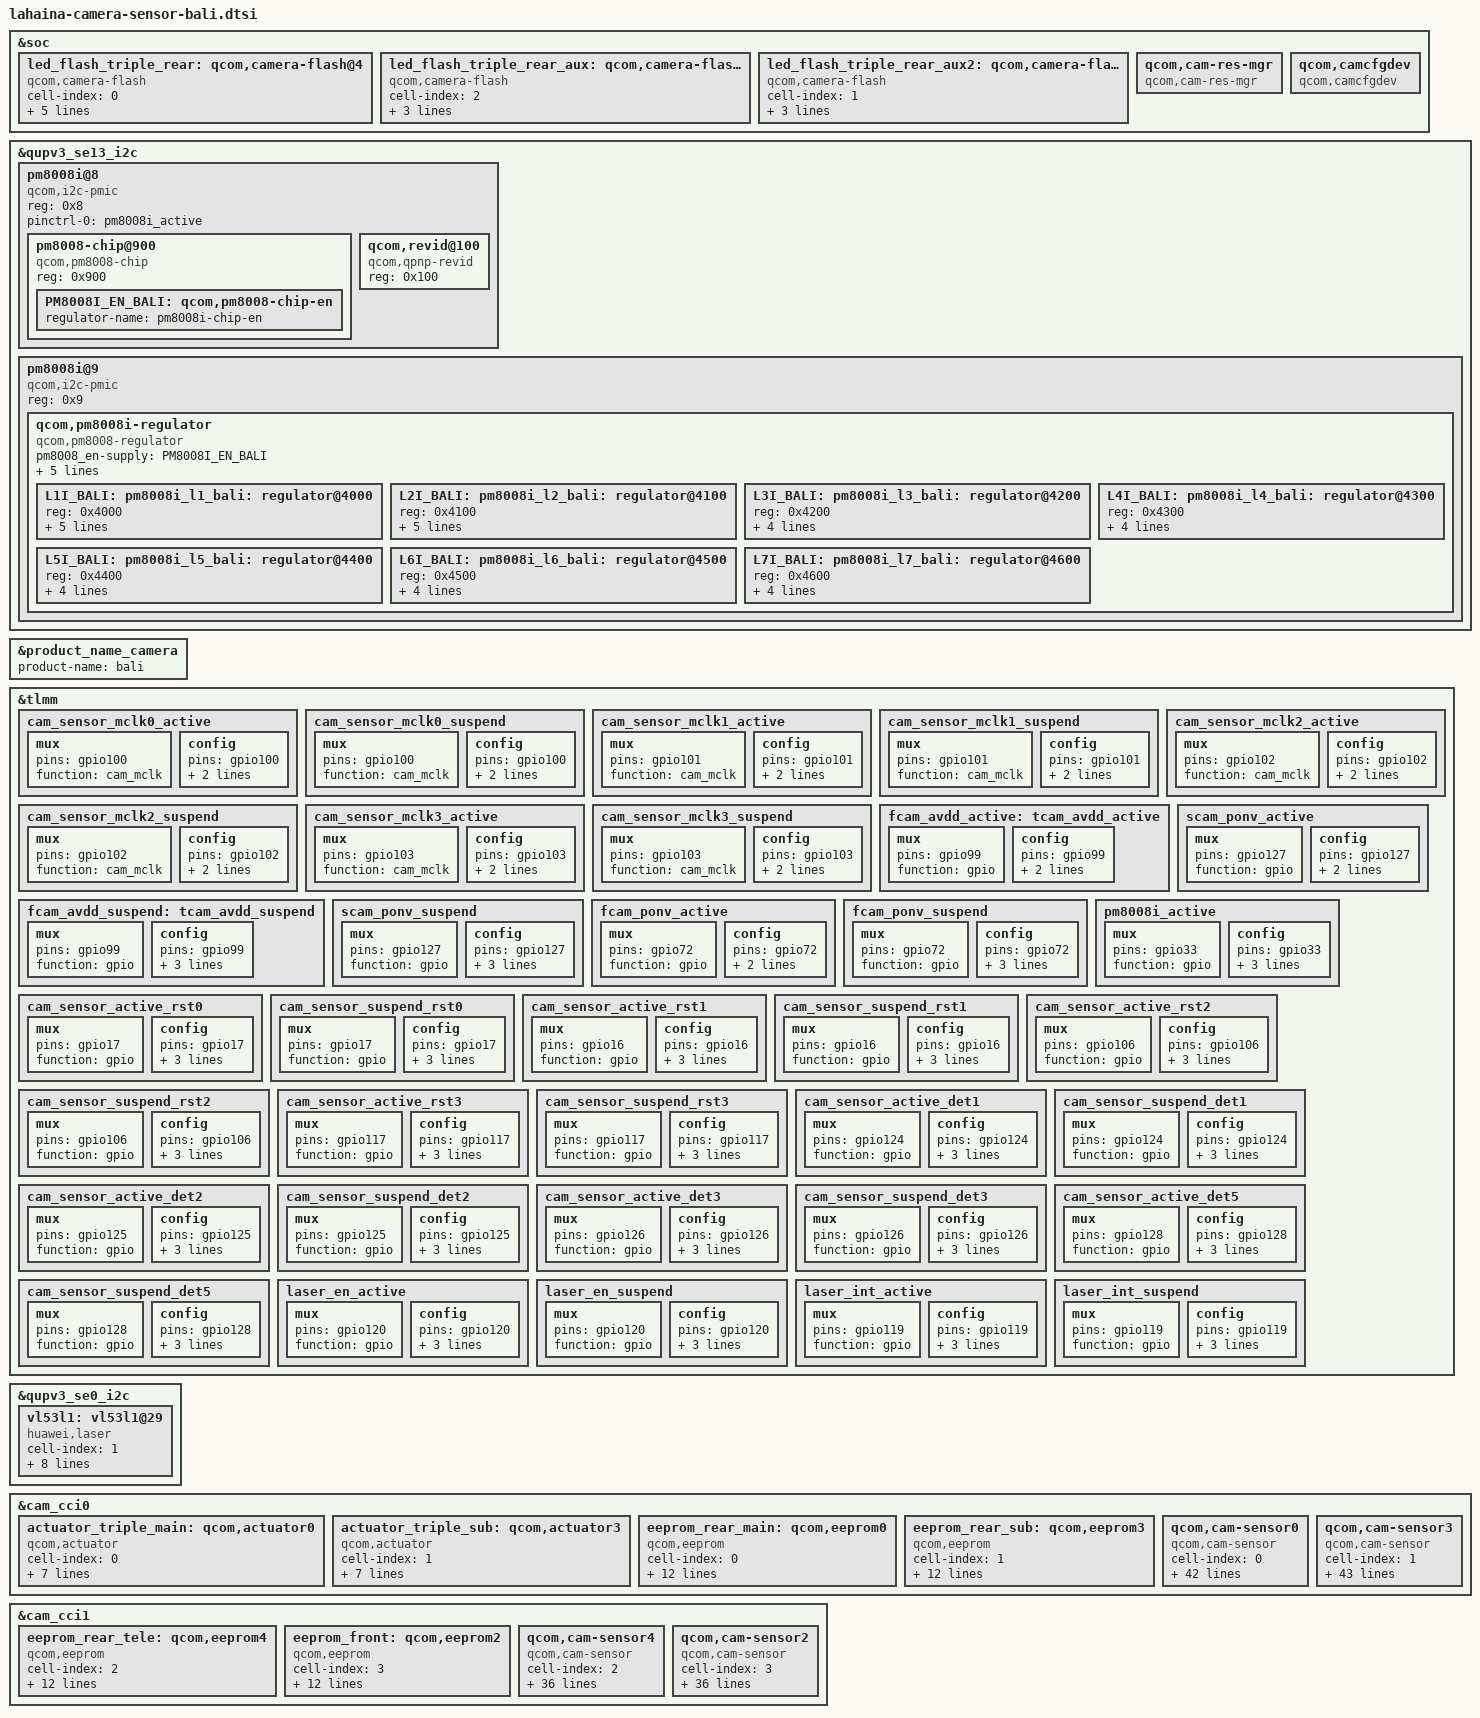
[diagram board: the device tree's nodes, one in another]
#include <dt-bindings/clock/qcom,camcc-lahaina.h>

&soc {
	led_flash_triple_rear: qcom,camera-flash@4 {
		cell-index = <0>;
		compatible = "qcom,camera-flash";
		flash-source = <&pm8350c_flash0 &pm8350c_flash1>;
		torch-source = <&pm8350c_torch0 &pm8350c_torch1>;
		switch-source = <&pm8350c_switch0>;
		torch-light-num = <0 1>;
		torch-light-name = "torch-light0", "torch-light1";
		status = "ok";
	};

	led_flash_triple_rear_aux: qcom,camera-flash@5 {
		cell-index = <2>;
		compatible = "qcom,camera-flash";
		flash-source = <&pm8350c_flash0 &pm8350c_flash1>;
		torch-source = <&pm8350c_torch0 &pm8350c_torch1>;
		switch-source = <&pm8350c_switch2>;
		status = "ok";
	};

	led_flash_triple_rear_aux2: qcom,camera-flash@6 {
		cell-index = <1>;
		compatible = "qcom,camera-flash";
		flash-source = <&pm8350c_flash0 &pm8350c_flash1>;
		torch-source = <&pm8350c_torch0 &pm8350c_torch1>;
		switch-source = <&pm8350c_switch2>;
		status = "ok";
	};

	qcom,cam-res-mgr {
		compatible = "qcom,cam-res-mgr";
		status = "ok";
	};
    qcom,camcfgdev {
        compatible = "qcom,camcfgdev";
        status = "ok";
    };
};

&qupv3_se13_i2c {
	#address-cells = <1>;
	#size-cells = <0>;
	status = "ok";

	pm8008i@8 {
		compatible = "qcom,i2c-pmic";
		reg = <0x8>;
		#address-cells = <1>;
		#size-cells = <0>;

		pinctrl-names = "default";
		pinctrl-0 = <&pm8008i_active>;

		pm8008-chip@900 {
			compatible = "qcom,pm8008-chip";
			reg = <0x900>;

			PM8008I_EN_BALI: qcom,pm8008-chip-en {
				regulator-name = "pm8008i-chip-en";
			};
		};

		qcom,revid@100 {
			compatible = "qcom,qpnp-revid";
			reg = <0x100>;
		};
	};

	pm8008i@9 {
		compatible = "qcom,i2c-pmic";
		reg = <0x9>;
		#address-cells = <1>;
		#size-cells = <0>;

		qcom,pm8008i-regulator {
			compatible = "qcom,pm8008-regulator";
			#address-cells = <1>;
			#size-cells = <0>;

			pm8008_en-supply = <&PM8008I_EN_BALI>;
			vdd_l1_l2-supply = <&S12B>;
			vdd_l3_l4-supply = <&S1C>;
			vdd_l5-supply = <&BOB>;
			vdd_l6-supply = <&S1C>;
			vdd_l7-supply = <&BOB>;

			L1I_BALI: pm8008i_l1_bali: regulator@4000 {
				reg = <0x4000>;
				regulator-name = "pm8008i_l1";
				regulator-min-microvolt = <944000>;
				regulator-max-microvolt = <1152000>;
				qcom,min-dropout-voltage = <150000>;
				qcom,hpm-min-load = <30000>;
			};

			L2I_BALI: pm8008i_l2_bali: regulator@4100 {
				reg = <0x4100>;
				regulator-name = "pm8008i_l2";
				regulator-min-microvolt = <944000>;
				regulator-max-microvolt = <1210000>;
				qcom,min-dropout-voltage = <150000>;
				qcom,hpm-min-load = <30000>;
			};

			L3I_BALI: pm8008i_l3_bali: regulator@4200 {
				reg = <0x4200>;
				regulator-name = "pm8008i_l3";
				regulator-min-microvolt = <1696000>;
				regulator-max-microvolt = <1800000>;
				qcom,min-dropout-voltage = <70000>;
			};

			L4I_BALI: pm8008i_l4_bali: regulator@4300 {
				reg = <0x4300>;
				regulator-name = "pm8008i_l4";
				regulator-min-microvolt = <1696000>;
				regulator-max-microvolt = <1800000>;
				qcom,min-dropout-voltage = <70000>;
			};

			L5I_BALI: pm8008i_l5_bali: regulator@4400 {
				reg = <0x4400>;
				regulator-name = "pm8008i_l5";
				regulator-min-microvolt = <2696000>;
				regulator-max-microvolt = <3000000>;
				qcom,min-dropout-voltage = <200000>;
			};

			L6I_BALI: pm8008i_l6_bali: regulator@4500 {
				reg = <0x4500>;
				regulator-name = "pm8008i_l6";
				regulator-min-microvolt = <1696000>;
				regulator-max-microvolt = <1800000>;
				qcom,min-dropout-voltage = <70000>;
			};

			L7I_BALI: pm8008i_l7_bali: regulator@4600 {
				reg = <0x4600>;
				regulator-name = "pm8008i_l7";
				regulator-min-microvolt = <2696000>;
				regulator-max-microvolt = <3240000>;
				qcom,min-dropout-voltage = <200000>;
			};
		};
	};
};

&product_name_camera {
    product-name = "bali";
};

&tlmm {
	cam_sensor_mclk0_active: cam_sensor_mclk0_active {
		/* MCLK0 */
		mux {
			pins = "gpio100";
			function = "cam_mclk";
		};

		config {
			pins = "gpio100";
			bias-disable; /* No PULL */
			drive-strength = <6>; /* 6 MA */
		};
	};

	cam_sensor_mclk0_suspend: cam_sensor_mclk0_suspend {
		/* MCLK0 */
		mux {
			pins = "gpio100";
			function = "cam_mclk";
		};

		config {
			pins = "gpio100";
			bias-pull-down; /* PULL DOWN */
			drive-strength = <6>; /* 6 MA */
		};
	};

	cam_sensor_mclk1_active: cam_sensor_mclk1_active {
		/* MCLK1 */
		mux {
			pins = "gpio101";
			function = "cam_mclk";
		};

		config {
			pins = "gpio101";
			bias-disable; /* No PULL */
			drive-strength = <6>; /* 6 MA */
		};
	};

	cam_sensor_mclk1_suspend: cam_sensor_mclk1_suspend {
		/* MCLK1 */
		mux {
			pins = "gpio101";
			function = "cam_mclk";
		};

		config {
			pins = "gpio101";
			bias-pull-down; /* PULL DOWN */
			drive-strength = <6>; /* 6 MA */
		};
	};

	cam_sensor_mclk2_active: cam_sensor_mclk2_active {
		/* MCLK2 */
		mux {
			pins = "gpio102";
			function = "cam_mclk";
		};

		config {
			pins = "gpio102";
			bias-disable; /* No PULL */
			drive-strength = <6>; /* 6 MA */
		};
	};

	cam_sensor_mclk2_suspend: cam_sensor_mclk2_suspend {
		/* MCLK2 */
		mux {
			pins = "gpio102";
			function = "cam_mclk";
		};

		config {
			pins = "gpio102";
			bias-pull-down; /* PULL DOWN */
			drive-strength = <6>; /* 6 MA */
		};
	};

	cam_sensor_mclk3_active: cam_sensor_mclk3_active {
		/* MCLK3 */
		mux {
			pins = "gpio103";
			function = "cam_mclk";
		};

		config {
			pins = "gpio103";
			bias-disable; /* No PULL */
			drive-strength = <6>; /* 6 MA */
		};
	};

	cam_sensor_mclk3_suspend: cam_sensor_mclk3_suspend {
		/* MCLK3 */
		mux {
			pins = "gpio103";
			function = "cam_mclk";
		};

		config {
			pins = "gpio103";
			bias-pull-down; /* PULL DOWN */
			drive-strength = <6>; /* 6 MA */
		};
	};

	fcam_avdd_active: tcam_avdd_active {
		/* AVDD for font */
		mux {
			pins = "gpio99";
			function = "gpio";
		};

		config {
			pins = "gpio99";
			bias-disable; /* No PULL */
			drive-strength = <2>; /* 2 MA */
		};
	};

	fcam_avdd_suspend: tcam_avdd_suspend {
		/* AVDD for font */
		mux {
			pins = "gpio99";
			function = "gpio";
		};

		config {
			pins = "gpio99";
			bias-pull-down; /* PULL DOWN */
			drive-strength = <2>; /* 2 MA */
			output-low;
		};
	};

	scam_ponv_active: scam_ponv_active {
		/* scam ponv */
		mux {
			pins = "gpio127";
			function = "gpio";
		};

		config {
			pins = "gpio127";
			bias-disable; /* No PULL */
			drive-strength = <2>; /* 2 MA */
		};
	};

	scam_ponv_suspend: scam_ponv_suspend {
		/* scam ponv */
		mux {
			pins = "gpio127";
			function = "gpio";
		};

		config {
			pins = "gpio127";
			bias-pull-down; /* PULL DOWN */
			drive-strength = <2>; /* 2 MA */
			output-low;
		};
	};

	fcam_ponv_active: fcam_ponv_active {
		/* fcam ponv */
		mux {
			pins = "gpio72";
			function = "gpio";
		};

		config {
			pins = "gpio72";
			bias-disable; /* No PULL */
			drive-strength = <2>; /* 2 MA */
		};
	};

	fcam_ponv_suspend: fcam_ponv_suspend {
		/* fcam ponv */
		mux {
			pins = "gpio72";
			function = "gpio";
		};

		config {
			pins = "gpio72";
			bias-pull-down; /* PULL DOWN */
			drive-strength = <2>; /* 2 MA */
			output-low;
		};
	};
	pm8008i_active: pm8008i_active {
		mux {
			pins = "gpio33";
			function = "gpio";
		};

		config {
			pins = "gpio33";
			bias-disable;
			output-high;
			drive-strength = <2>;
		};
	};

	cam_sensor_active_rst0: cam_sensor_active_rst0 {
		/* RESET 0 */
		mux {
			pins = "gpio17";
			function = "gpio";
		};

		config {
			pins = "gpio17";
			bias-disable; /* No PULL */
			drive-strength = <2>; /* 2 MA */
			input-enable;
		};
	};

	cam_sensor_suspend_rst0: cam_sensor_suspend_rst0 {
		/* RESET 0 */
		mux {
			pins = "gpio17";
			function = "gpio";
		};

		config {
			pins = "gpio17";
			bias-pull-down; /* PULL DOWN */
			drive-strength = <2>; /* 2 MA */
			output-low;
		};
	};

	cam_sensor_active_rst1: cam_sensor_active_rst1 {
		/* RESET 1 */
		mux {
			pins = "gpio16";
			function = "gpio";
		};

		config {
			pins = "gpio16";
			bias-disable; /* No PULL */
			drive-strength = <2>; /* 2 MA */
			input-enable;
		};
	};

	cam_sensor_suspend_rst1: cam_sensor_suspend_rst1 {
		/* RESET 1 */
		mux {
			pins = "gpio16";
			function = "gpio";
		};

		config {
			pins = "gpio16";
			bias-pull-down; /* PULL DOWN */
			drive-strength = <2>; /* 2 MA */
			output-low;
		};
	};

	cam_sensor_active_rst2: cam_sensor_active_rst2 {
		/* RESET 2 */
		mux {
			pins = "gpio106";
			function = "gpio";
		};

		config {
			pins = "gpio106";
			bias-disable; /* No PULL */
			drive-strength = <2>; /* 2 MA */
			input-enable;
		};
	};

	cam_sensor_suspend_rst2: cam_sensor_suspend_rst2 {
		/* RESET 2 */
		mux {
			pins = "gpio106";
			function = "gpio";
		};

		config {
			pins = "gpio106";
			bias-pull-down; /* PULL DOWN */
			drive-strength = <2>; /* 2 MA */
			output-low;
		};
	};

	cam_sensor_active_rst3: cam_sensor_active_rst3 {
		/* RESET 3 */
		mux {
			pins = "gpio117";
			function = "gpio";
		};

		config {
			pins = "gpio117";
			bias-disable; /* No PULL */
			drive-strength = <2>; /* 2 MA */
			input-enable;
		};
	};

	cam_sensor_suspend_rst3: cam_sensor_suspend_rst3 {
		/* RESET 3 */
		mux {
			pins = "gpio117";
			function = "gpio";
		};

		config {
			pins = "gpio117";
			bias-pull-down; /* PULL DOWN */
			drive-strength = <2>; /* 2 MA */
			output-low;
		};
	};

	cam_sensor_active_det1: cam_sensor_active_det1 {
		/* BTB_DET 1 */
		mux {
			pins = "gpio124";
			function = "gpio";
		};

		config {
			pins = "gpio124";
			bias-disable; /* No PULL */
			drive-strength = <2>; /* 2 MA */
			input-enable;
		};
	};

	cam_sensor_suspend_det1: cam_sensor_suspend_det1 {
		/* BTB_DET 1 */
		mux {
			pins = "gpio124";
			function = "gpio";
		};

		config {
			pins = "gpio124";
			bias-disable; /* No PULL */
			drive-strength = <2>; /* 2 MA */
			input-enable;
		};
	};

	cam_sensor_active_det2: cam_sensor_active_det2 {
		/* BTB_DET 2 */
		mux {
			pins = "gpio125";
			function = "gpio";
		};

		config {
			pins = "gpio125";
			bias-disable; /* No PULL */
			drive-strength = <2>; /* 2 MA */
			input-enable;
		};
	};

	cam_sensor_suspend_det2: cam_sensor_suspend_det2 {
		/* BTB_DET 2 */
		mux {
			pins = "gpio125";
			function = "gpio";
		};

		config {
			pins = "gpio125";
			bias-disable; /* No PULL */
			drive-strength = <2>; /* 2 MA */
			input-enable;
		};
	};

	cam_sensor_active_det3: cam_sensor_active_det3 {
		/* BTB_DET 3 */
		mux {
			pins = "gpio126";
			function = "gpio";
		};

		config {
			pins = "gpio126";
			bias-disable; /* No PULL */
			drive-strength = <2>; /* 2 MA */
			input-enable;
		};
	};

	cam_sensor_suspend_det3: cam_sensor_suspend_det3 {
		/* BTB_DET 3 */
		mux {
			pins = "gpio126";
			function = "gpio";
		};

		config {
			pins = "gpio126";
			bias-disable; /* No PULL */
			drive-strength = <2>; /* 2 MA */
			input-enable;
		};
	};

	cam_sensor_active_det5: cam_sensor_active_det5 {
		/* BTB_DET 5 */
		mux {
			pins = "gpio128";
			function = "gpio";
		};

		config {
			pins = "gpio128";
			bias-disable; /* No PULL */
			drive-strength = <2>; /* 2 MA */
			input-enable;
		};
	};

	cam_sensor_suspend_det5: cam_sensor_suspend_det5 {
		/* BTB_DET 5 */
		mux {
			pins = "gpio128";
			function = "gpio";
		};

		config {
			pins = "gpio128";
			bias-disable; /* No PULL */
			drive-strength = <2>; /* 2 MA */
			input-enable;
		};
	};

	laser_en_active: laser_en_active {
		/* laser en pin */
		mux {
			pins = "gpio120";
			function = "gpio";
		};

		config {
			pins = "gpio120";
			bias-pull-up; /* PULL UP */
			drive-strength = <2>; /* 2 MA */
			input-enable;
		};
	};

	laser_en_suspend: laser_en_suspend {
		/* laser en pin */
		mux {
			pins = "gpio120";
			function = "gpio";
		};

		config {
			pins = "gpio120";
			bias-pull-up; /* PULL UP */
			drive-strength = <2>; /* 2 MA */
			input-enable;
		};
	};

	laser_int_active: laser_int_active {
		/* laser int pin */
		mux {
			pins = "gpio119";
			function = "gpio";
		};

		config {
			pins = "gpio119";
			bias-pull-up; /* PULL UP */
			drive-strength = <2>; /* 2 MA */
			input-enable;
		};
	};

	laser_int_suspend: laser_int_suspend {
		/* laser int pin */
		mux {
			pins = "gpio119";
			function = "gpio";
		};

		config {
			pins = "gpio119";
			bias-pull-up; /* PULL UP */
			drive-strength = <2>; /* 2 MA */
			input-enable;
		};
	};
};

/* laser */
&qupv3_se0_i2c {
	status = "ok";

	vl53l1: vl53l1@29 {
		cell-index = <1>;
		compatible = "huawei,laser";
		reg = <0x29>;
		vdd_ana-supply = <&pm8350_l7>;
		gpios = <&tlmm 120 0>,
			<&tlmm 119 0>;
		pinctrl-names = "laser_int_active", "laser_en_active";
		pinctrl-0 = <&laser_int_active>;
		pinctrl-1 = <&laser_en_active>;
		gpio-req-tbl-num = <0>;
		gpio-req-tbl-flags = <0>;
		gpio-req-tbl-label = "CAM_VAF0";
		status = "ok";
	};
};

&cam_cci0 {
	actuator_triple_main: qcom,actuator0 {
		cell-index = <0>;
		compatible = "qcom,actuator";
		cci-master = <0>;
		cam_vaf-supply = <&pm8008i_l7_bali>;
		regulator-names = "cam_vaf";
		rgltr-cntrl-support;
		rgltr-min-voltage = <3200000>;
		rgltr-max-voltage = <3200000>;
		rgltr-load-current = <103000>;
	};

	actuator_triple_sub: qcom,actuator3 {
		cell-index = <1>;
		compatible = "qcom,actuator";
		cci-master = <1>;
		cam_vaf-supply = <&pm8008i_l7_bali>;
		regulator-names = "cam_vaf";
		rgltr-cntrl-support;
		rgltr-min-voltage = <3200000>;
		rgltr-max-voltage = <3200000>;
		rgltr-load-current = <103000>;
	};

	eeprom_rear_main: qcom,eeprom0 {
		cell-index = <0>;
		compatible = "qcom,eeprom";
		cam_vio-supply = <&pm8008i_l6_bali>;
		cam_clk-supply = <&cam_cc_titan_top_gdsc>;
		regulator-names = "cam_vio", "cam_clk";
		rgltr-cntrl-support;
		rgltr-min-voltage = <1800000 0>;
		rgltr-max-voltage = <1900000 0>;
		rgltr-load-current = <74000 0>;
		gpio-no-mux = <0>;
		cci-master = <0>;
		status = "ok";
		clocks = <&clock_camcc CAM_CC_MCLK0_CLK>;
		clock-names = "cam_clk";
		clock-cntl-level = "nominal";
		clock-rates = <19200000>;
	};

	eeprom_rear_sub: qcom,eeprom3 {
		cell-index = <1>;
		compatible = "qcom,eeprom";
		cam_vio-supply = <&pm8008i_l6_bali>;
		cam_clk-supply = <&cam_cc_titan_top_gdsc>;
		regulator-names = "cam_vio", "cam_clk";
		rgltr-cntrl-support;
		rgltr-min-voltage = <1800000 0>;
		rgltr-max-voltage = <1900000 0>;
		rgltr-load-current = <74000 0>;
		gpio-no-mux = <0>;
		cci-master = <1>;
		status = "ok";
		clocks = <&clock_camcc CAM_CC_MCLK1_CLK>;
		clock-names = "cam_clk";
		clock-cntl-level = "nominal";
		clock-rates = <19200000>;
	};

	/* back main sensor */
	qcom,cam-sensor0 {
		cell-index = <0>;
		compatible = "qcom,cam-sensor";
		csiphy-sd-index = <1>;
		sensor-position-roll = <90>;
		sensor-position-pitch = <0>;
		sensor-position-yaw = <180>;
		eeprom-src = <&eeprom_rear_main>;
		actuator-src = <&actuator_triple_main>;
		led-flash-src = <&led_flash_triple_rear>;
		cam_vio-supply = <&pm8008i_l6_bali>;
		cam_v_custom1-supply = <&pm8008i_l5_bali>;
		cam_vana-supply = <&pm8008i_l4_bali>;
		cam_vdig-supply = <&pm8008i_l1_bali>;
		cam_vaf-supply = <&pm8008i_l7_bali>;
		cam_clk-supply = <&cam_cc_titan_top_gdsc>;
		regulator-names = "cam_vio", "cam_v_custom1", "cam_vana", "cam_vdig", "cam_vaf", "cam_clk";
		rgltr-cntrl-support;
		rgltr-min-voltage = <1800000 2850000 1800000 1150000 3200000 0>;
		rgltr-max-voltage = <1900000 2900000 1900000 1250000 3200000 0>;
		rgltr-load-current = <805000 103000 805000 805000 103000 0>;
		gpio-no-mux = <0>;
		pinctrl-names = "cam_default", "cam_suspend";
		pinctrl-0 = <&cam_sensor_mclk0_active
				&cam_sensor_active_rst1
				&cam_sensor_active_det1>;
		pinctrl-1 = <&cam_sensor_mclk0_suspend
				&cam_sensor_suspend_rst1
				&cam_sensor_suspend_det1>;
		gpios = <&tlmm 100 0>,
			<&tlmm 16 0>,
			<&tlmm 124 0>;
		gpio-reset = <1>;
		gpio-btb-det = <2>;
		gpio-req-tbl-num = <0 1 2>;
		gpio-req-tbl-flags = <1 0 0>;
		gpio-req-tbl-label = "CAMIF_MCLK0",
					"CAM_RESET0",
					"CAM_BTB_DET1";
		cci-master = <0>;
		status = "ok";
		clocks = <&clock_camcc CAM_CC_MCLK0_CLK>;
		clock-names = "cam_clk";
		clock-cntl-level = "nominal";
		clock-rates = <19200000>;
		ic_position = <0>; /* CAMERA_POSITION_REAR */
		btb_check = <1>; /* need btb check */
	};
	/* back sub sensor */
	qcom,cam-sensor3 {
		cell-index = <1>;
		compatible = "qcom,cam-sensor";
		csiphy-sd-index = <2>;
		sensor-position-roll = <90>;
		sensor-position-pitch = <0>;
		sensor-position-yaw = <180>;
		actuator-src = <&actuator_triple_sub>;
		eeprom-src = <&eeprom_rear_sub>;
		led-flash-src = <&led_flash_triple_rear_aux2>;
		cam_vio-supply = <&pm8008i_l6_bali>;
		cam_vana-supply = <&pm8008i_l3_bali>;
		cam_v_custom1-supply = <&pm8008i_l5_bali>;
		cam_vdig-supply = <&pm8008i_l2_bali>;
		cam_vaf-supply = <&pm8008i_l7_bali>;
		cam_clk-supply = <&cam_cc_titan_top_gdsc>;
		regulator-names = "cam_vio", "cam_vana", "cam_v_custom1", "cam_vdig", "cam_vaf", "cam_clk";
		rgltr-cntrl-support;
		rgltr-min-voltage = <1800000 1800000 2850000 1150000 3200000 0>;
		rgltr-max-voltage = <1900000 1900000 2900000 1250000 3200000 0>;
		rgltr-load-current = <74000 74000 200000 140000 103000 0>;
		gpio-no-mux = <0>;
		pinctrl-names = "cam_default", "cam_suspend";
		pinctrl-0 = <&cam_sensor_mclk1_active
				&scam_ponv_active
				&cam_sensor_active_rst2
				&cam_sensor_active_det2>;
		pinctrl-1 = <&cam_sensor_mclk1_suspend
				&scam_ponv_suspend
				&cam_sensor_suspend_rst2
				&cam_sensor_suspend_det2>;
		gpios = <&tlmm 101 0>,
			<&tlmm 127 0>,
			<&tlmm 106 0>,
			<&tlmm 125 0>;
		gpio-custom1 = <1>;
		gpio-reset = <2>;
		gpio-btb-det = <3>;
		gpio-req-tbl-num = <0 1 2 3>;
		gpio-req-tbl-flags = <1 0 0 0>;
		gpio-req-tbl-label = "CAMIF_MCLK1",
					"CAM_SUB_PONV",
					"CAM_RESET4",
					"CAM_BTB_DET2";
		cci-master = <1>;
		status = "ok";
		clocks = <&clock_camcc CAM_CC_MCLK1_CLK>;
		clock-names = "cam_clk";
		clock-cntl-level = "nominal";
		clock-rates = <19200000>;
		ic_position = <2>; /* CAMERA_POSITION_REAR_SECOND */
		btb_check = <1>; /* need btb check */
	};
};

&cam_cci1 {
	eeprom_rear_tele: qcom,eeprom4 {
		cell-index = <2>;
		compatible = "qcom,eeprom";
		cam_vio-supply = <&pm8008i_l6_bali>;
		cam_clk-supply = <&cam_cc_titan_top_gdsc>;
		regulator-names = "cam_vio", "cam_clk";
		rgltr-cntrl-support;
		rgltr-min-voltage = <1800000 0>;
		rgltr-max-voltage = <1900000 0>;
		rgltr-load-current = <74000 0>;
		gpio-no-mux = <0>;
		cci-master = <0>;
		status = "ok";
		clocks = <&clock_camcc CAM_CC_MCLK2_CLK>;
		clock-names = "cam_clk";
		clock-cntl-level = "nominal";
		clock-rates = <19200000>;
	};

	eeprom_front: qcom,eeprom2 {
		cell-index = <3>;
		compatible = "qcom,eeprom";
		cam_vio-supply = <&pm8008i_l6_bali>;
		cam_clk-supply = <&cam_cc_titan_top_gdsc>;
		regulator-names = "cam_vio", "cam_clk";
		rgltr-cntrl-support;
		rgltr-min-voltage = <1800000 0>;
		rgltr-max-voltage = <1900000 0>;
		rgltr-load-current = <74000 0>;
		gpio-no-mux = <0>;
		cci-master = <1>;
		status = "ok";
		clocks = <&clock_camcc CAM_CC_MCLK3_CLK>;
		clock-names = "cam_clk";
		clock-cntl-level = "nominal";
		clock-rates = <19200000>;
	};

	/* back tele sensor */
	qcom,cam-sensor4 {
		cell-index = <2>;
		compatible = "qcom,cam-sensor";
		csiphy-sd-index = <3>;
		sensor-position-roll = <90>;
		sensor-position-pitch = <0>;
		sensor-position-yaw = <180>;
		eeprom-src = <&eeprom_rear_tele>;
		led-flash-src = <&led_flash_triple_rear_aux>;
		cam_vio-supply = <&pm8008i_l6_bali>;
		cam_vana-supply = <&pm8008i_l5_bali>;
		cam_vdig-supply = <&pm8008i_l2_bali>;
		cam_clk-supply = <&cam_cc_titan_top_gdsc>;
		regulator-names = "cam_vio", "cam_vana", "cam_vdig", "cam_clk";
		rgltr-cntrl-support;
		rgltr-min-voltage = <1800000 2850000 1150000 0>;
		rgltr-max-voltage = <1900000 2900000 1250000 0>;
		rgltr-load-current = <74000 200000 140000 0>;
		gpio-no-mux = <0>;
		pinctrl-names = "cam_default", "cam_suspend";
		pinctrl-0 = <&cam_sensor_mclk2_active
				&cam_sensor_active_rst3
				&cam_sensor_active_det3>;
		pinctrl-1 = <&cam_sensor_mclk2_suspend
				&cam_sensor_suspend_rst3
				&cam_sensor_suspend_det3>;
		gpios = <&tlmm 102 0>,
			<&tlmm 117 0>,
			<&tlmm 126 0>;
		gpio-reset = <1>;
		gpio-btb-det = <2>;
		gpio-req-tbl-num = <0 1 2>;
		gpio-req-tbl-flags = <1 0 0>;
		gpio-req-tbl-label = "CAMIF_MCLK2",
					"CAM_RESET5",
					"CAM_BTB_DET3";
		cci-master = <0>;
		status = "ok";
		clocks = <&clock_camcc CAM_CC_MCLK2_CLK>;
		clock-names = "cam_clk";
		clock-cntl-level = "nominal";
		clock-rates = <19200000>;
		ic_position = <4>; /* CAMERA_POSITION_REAR_THIRD */
		btb_check = <1>; /* need btb check */
	};

	/* front sensor */
	qcom,cam-sensor2 {
		cell-index = <3>;
		compatible = "qcom,cam-sensor";
		csiphy-sd-index = <0>;
		sensor-position-roll = <270>;
		sensor-position-pitch = <0>;
		sensor-position-yaw = <0>;
		eeprom-src = <&eeprom_front>;
		cam_vdig-supply = <&pm8008i_l1_bali>;
		cam_vana-supply = <&pm8008i_l3_bali>;
		cam_v_custom1-supply = <&pm8008i_l5_bali>;
		cam_clk-supply = <&cam_cc_titan_top_gdsc>;
		regulator-names = "cam_vdig", "cam_vana", "cam_v_custom1", "cam_clk";
		rgltr-cntrl-support;
		rgltr-min-voltage = <1150000 1800000 2850000 0>;
		rgltr-max-voltage = <1250000 1900000 2900000 0>;
		rgltr-load-current = <140000 74000 52000 0>;
		gpio-no-mux = <0>;
		pinctrl-names = "cam_default", "cam_suspend";
		pinctrl-0 = <&cam_sensor_mclk3_active
				&cam_sensor_active_rst0
				&fcam_ponv_active
				&cam_sensor_active_det5>;
		pinctrl-1 = <&cam_sensor_mclk3_suspend
				&cam_sensor_suspend_rst0
				&fcam_ponv_suspend
				&cam_sensor_suspend_det5>;
		gpios = <&tlmm 103 0>,
			<&tlmm 17 0>,
			<&tlmm 72 0>,
			<&tlmm 128 0>;
		gpio-reset = <1>;
		gpio-custom1 = <2>;
		gpio-btb-det = <3>;
		gpio-req-tbl-num = <0 1 2 3>;
		gpio-req-tbl-flags = <1 0 0 0>;
		gpio-req-tbl-label = "CAMIF_MCLK3",
					"CAM_RESET2",
					"CAM_FONT_CUSTOM1",
					"CAM_BTB_DET5";
		cci-master = <1>;
		status = "ok";
		clocks = <&clock_camcc CAM_CC_MCLK3_CLK>;
		clock-names = "cam_clk";
		clock-cntl-level = "nominal";
		clock-rates = <19200000>;
		ic_position = <1>; /* CAMERA_POSITION_FORE */
		btb_check = <1>; /* need btb check */
	};
};
